# STM32H7B3xxQ register map
File version: 1.0
Registers are 32-bit, read-write, reset 0x0 unless marked. A register's access mark holds for its fields unless they carry their own. Offsets are from the block's base; [hi:lo] are bit positions; {n}, {i} and the like mark numbered series; 'fields as' and 'values as' point back to an identical list.

## DFSDM1_Channel0 — DFSDM channel configuration registers
Base 0x40017800
Same registers: DFSDM1_Channel1 0x40017820, DFSDM1_Channel2 0x40017840, DFSDM1_Channel3 0x40017860, DFSDM1_Channel4 0x40017880, DFSDM1_Channel5 0x400178A0, DFSDM1_Channel6 0x400178C0, DFSDM1_Channel7 0x400178E0
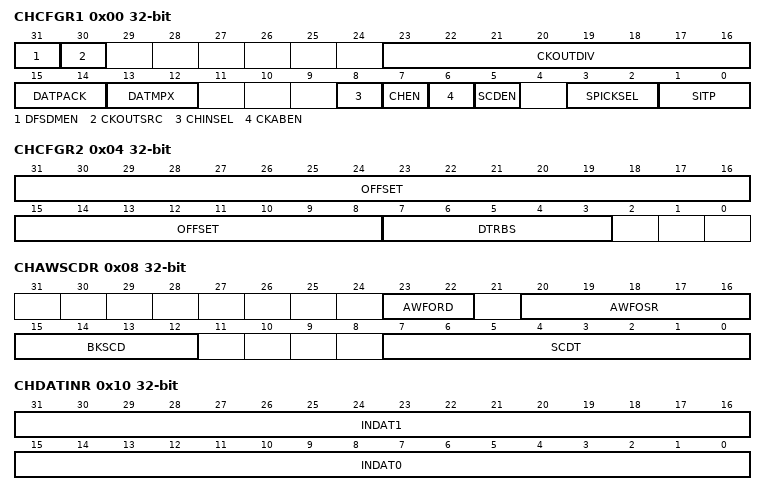
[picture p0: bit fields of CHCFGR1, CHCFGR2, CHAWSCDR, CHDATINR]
0x00 CHCFGR1 — DFSDM channel configuration register1
  [31] DFSDMEN — Global enable for DFSDM interface
  [30] CKOUTSRC — Output serial clock source selection
  [23:16] CKOUTDIV — CKOUTDIV[7:0] output serial clock divider
  [15:14] DATPACK — DATPACK[1:0] Data packing mode
  [13:12] DATMPX — DATMPX[1:0] Input data multiplexer for channel y
  [8] CHINSEL — Serial inputs selection for channel y
  [7] CHEN — Channel y enable
  [6] CKABEN — Clock absence detector enable on channel y
  [5] SCDEN — Short circuit detector enable on channel y
  [3:2] SPICKSEL — SPICKSEL[1:0] SPI clock select for channel y
  [1:0] SITP — SITP[1:0] Serial interface type for channel y
0x04 CHCFGR2 — DFSDM channel configuration register2
  [31:8] OFFSET — OFFSET[23:0] 24-bit calibration offset for channel y
  [7:3] DTRBS — DTRBS[4:0] Data right bit-shift for channel y
0x08 CHAWSCDR — DFSDM channel analog watchdog and short circuit detector register
  [23:22] AWFORD — AWFORD[1:0] Analog watchdog Sinc filter order on channel y
  [20:16] AWFOSR — AWFOSR[4:0] Analog watchdog filter oversampling ratio on channel y
  [15:12] BKSCD — BKSCD[3:0] Break signal assignment for short circuit detector on channel y
  [7:0] SCDT — SCDT[7:0] Short circuit detector threshold for channel y
0x0C CHWDATAR — DFSDM channel watchdog filter data register
0x10 CHDATINR — DFSDM channel data input register
  [31:16] INDAT1 — INDAT0[15:0] Input data for channel y
  [15:0] INDAT0 — INDAT0[31:16] Input data for channel y or channel (y+1)
0x14 CHDLYR — DFSDM channel delay register
  [5:0] PLSSKP

## DMAMUX1
Base 0x40020800
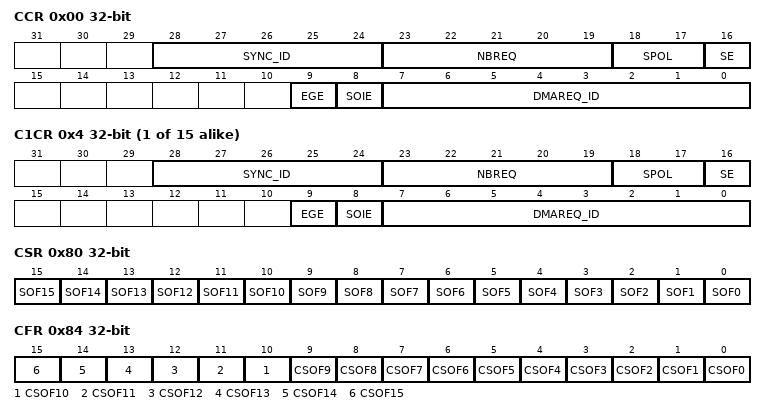
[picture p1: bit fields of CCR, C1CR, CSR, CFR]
0x00 CCR — DMA Multiplexer Channel x Control Register
  [28:24] SYNC_ID — Synchronization identification
  [23:19] NBREQ — Number of DMA requests minus 1 to forward
  [18:17] SPOL — Synchronization polarity
  [16] SE — Synchronization enable
  [9] EGE — Event generation enable
  [8] SOIE — Synchronization overrun interrupt enable
  [7:0] DMAREQ_ID — DMA request identification
{0x0+4i} C{i}CR (i=1..15) — DMA Multiplexer Channel x Control Register
  fields as CCR
0x80 CSR — DMA Channel Status Register
  [n] SOF{n} (n=0..15) — Channel {n} Synchronization overrun event flag
0x84 CFR — DMA Channel Clear Flag Register
  [n] CSOF{n} (n=0..15) — Channel {n} Clear synchronization overrun event flag
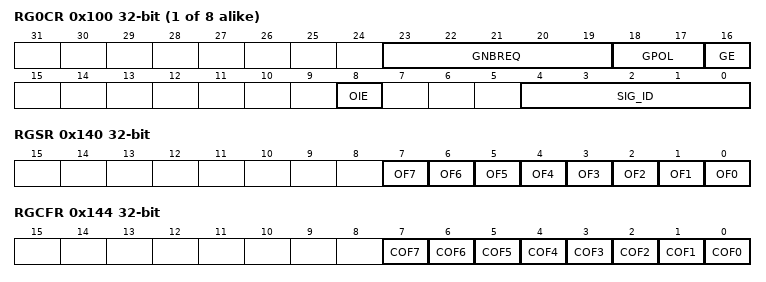
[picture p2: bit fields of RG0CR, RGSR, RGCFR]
{0x100+4i} RG{i}CR (i=0..7) — DMA Request Generator x Control Register
  [23:19] GNBREQ — Number of DMA requests to be generated
  [18:17] GPOL — DMA request generator trigger polarity
  [16] GE — DMA request generator enable
  [8] OIE — Trigger overrun interrupt enable
  [4:0] SIG_ID — Signal identification
0x140 RGSR — DMA Request Generator Status Register
  [n] OF{n} (n=0..7) — Request generator channel {n} Trigger overrun event flag
0x144 RGCFR — DMA Request Generator Clear Flag Register
  [n] COF{n} (n=0..7) — Request generator channel {n} Clear trigger overrun event flag

## DMAMUX2
Base 0x58025800
Registers as DMAMUX1, without C{n}CR (n=8..15).

## CRC — CRC calculation unit
Base 0x40023000
0x00 DR — CRC Data register
  [31:0] DR — Data register bits
0x04 IDR — CRC Independent data register
  [31:0] IDR — General-purpose 32-bit data register bits
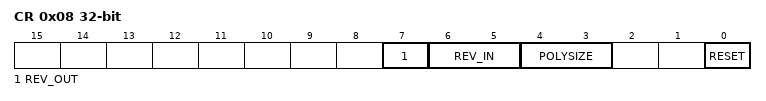
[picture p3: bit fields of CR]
0x08 CR — CRC Control register
  [7] REV_OUT — REV_OUT Reverse Output Data bits
    0=NONE (Output Data bit order not affected); 1=BIT (Output Data bit reversal done by bit)
  [6:5] REV_IN — REV_IN Reverse Input Data bits
    0=NONE (Input Data bit order not affected); 1=BYTE (Input Data bit reversal done by byte); 2=HALFWORD (Input Data bit reversal done by half-word); 3=WORD (Input Data bit reversal done by word)
  [4:3] POLYSIZE — Polynomial size bits
    0=POLYLENGTH_32B (32 bits Polynomial size); 1=POLYLENGTH_16B (16 bits Polynomial size); 2=POLYLENGTH_8B (8 bits Polynomial size); 3=POLYLENGTH_7B (7 bits Polynomial size)
  [0] RESET — RESET the CRC computation unit bit
0x10 INIT — Initial CRC value register
  [31:0] INIT — Initial CRC value bits
0x14 POL — CRC polynomial register
  [31:0] POL — Coefficients of the polynomial
